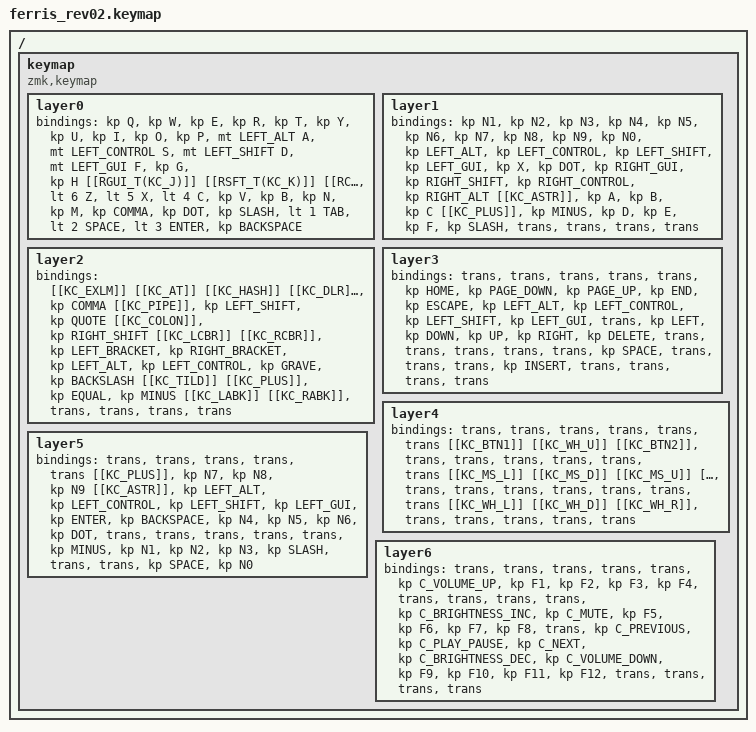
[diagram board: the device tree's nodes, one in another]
/*
 * Copyright (c) 2020 The ZMK Contributors
 *
 * SPDX-License-Identifier: MIT
 */

  /*
  * Copyright (c) 2020 The ZMK Contributors
  *
  * SPDX-License-Identifier: MIT
  */

  #include <behaviors.dtsi>
  #include <dt-bindings/zmk/keys.h>
  #include <dt-bindings/zmk/bt.h>
  #include <dt-bindings/zmk/ext_power.h>

  / {
    keymap {
      compatible = "zmk,keymap";
  layer0 {
          bindings = <
          &kp Q &kp W &kp E &kp R &kp T &kp Y &kp U &kp I &kp O &kp P &mt LEFT_ALT A &mt LEFT_CONTROL S &mt LEFT_SHIFT D &mt LEFT_GUI F &kp G &kp H [[RGUI_T(KC_J)]] [[RSFT_T(KC_K)]] [[RCTL_T(KC_L)]] [[RALT_T(KC_SCLN)]] &lt 6 Z &lt 5 X &lt 4 C &kp V &kp B &kp N &kp M &kp COMMA &kp DOT &kp SLASH &lt 1 TAB &lt 2 SPACE &lt 3 ENTER &kp BACKSPACE
          >;
        };layer1 {
          bindings = <
          &kp N1 &kp N2 &kp N3 &kp N4 &kp N5 &kp N6 &kp N7 &kp N8 &kp N9 &kp N0 &kp LEFT_ALT &kp LEFT_CONTROL &kp LEFT_SHIFT &kp LEFT_GUI &kp X &kp DOT &kp RIGHT_GUI &kp RIGHT_SHIFT &kp RIGHT_CONTROL &kp RIGHT_ALT [[KC_ASTR]] &kp A &kp B &kp C [[KC_PLUS]] &kp MINUS &kp D &kp E &kp F &kp SLASH &trans &trans &trans &trans
          >;
        };layer2 {
          bindings = <
          [[KC_EXLM]] [[KC_AT]] [[KC_HASH]] [[KC_DLR]] [[KC_PERC]] [[KC_CIRC]] [[KC_AMPR]] [[KC_ASTR]] [[KC_LPRN]] [[KC_RPRN]] &kp COMMA [[KC_PIPE]] &kp LEFT_SHIFT &kp QUOTE [[KC_COLON]] &kp RIGHT_SHIFT [[KC_LCBR]] [[KC_RCBR]] &kp LEFT_BRACKET &kp RIGHT_BRACKET &kp LEFT_ALT &kp LEFT_CONTROL &kp GRAVE &kp BACKSLASH [[KC_TILD]] [[KC_PLUS]] &kp EQUAL &kp MINUS [[KC_LABK]] [[KC_RABK]] &trans &trans &trans &trans
          >;
        };layer3 {
          bindings = <
          &trans &trans &trans &trans &trans &kp HOME &kp PAGE_DOWN &kp PAGE_UP &kp END &kp ESCAPE &kp LEFT_ALT &kp LEFT_CONTROL &kp LEFT_SHIFT &kp LEFT_GUI &trans &kp LEFT &kp DOWN &kp UP &kp RIGHT &kp DELETE &trans &trans &trans &trans &trans &kp SPACE &trans &trans &trans &kp INSERT &trans &trans &trans &trans
          >;
        };layer4 {
          bindings = <
          &trans &trans &trans &trans &trans &trans [[KC_BTN1]] [[KC_WH_U]] [[KC_BTN2]] &trans &trans &trans &trans &trans &trans [[KC_MS_L]] [[KC_MS_D]] [[KC_MS_U]] [[KC_MS_R]] &trans &trans &trans &trans &trans &trans &trans [[KC_WH_L]] [[KC_WH_D]] [[KC_WH_R]] &trans &trans &trans &trans &trans
          >;
        };layer5 {
          bindings = <
          &trans &trans &trans &trans &trans [[KC_PLUS]] &kp N7 &kp N8 &kp N9 [[KC_ASTR]] &kp LEFT_ALT &kp LEFT_CONTROL &kp LEFT_SHIFT &kp LEFT_GUI &kp ENTER &kp BACKSPACE &kp N4 &kp N5 &kp N6 &kp DOT &trans &trans &trans &trans &trans &kp MINUS &kp N1 &kp N2 &kp N3 &kp SLASH &trans &trans &kp SPACE &kp N0
          >;
        };layer6 {
          bindings = <
          &trans &trans &trans &trans &trans &kp C_VOLUME_UP &kp F1 &kp F2 &kp F3 &kp F4 &trans &trans &trans &trans &kp C_BRIGHTNESS_INC &kp C_MUTE &kp F5 &kp F6 &kp F7 &kp F8 &trans &kp C_PREVIOUS &kp C_PLAY_PAUSE &kp C_NEXT &kp C_BRIGHTNESS_DEC &kp C_VOLUME_DOWN &kp F9 &kp F10 &kp F11 &kp F12 &trans &trans &trans &trans
          >;
        };
    };
  };
